# CTRL_MMR0_CFG0 register map
Vendor: Texas Instruments
Registers are 32-bit, read-write, reset 0x0 unless marked. A register's access mark holds for its fields unless they carry their own. Offsets are as the file gives them; [hi:lo] are bit positions; {n}, {i} and the like mark numbered series.

## CTRL_MMR0_CFG0 (part 4 of 10)
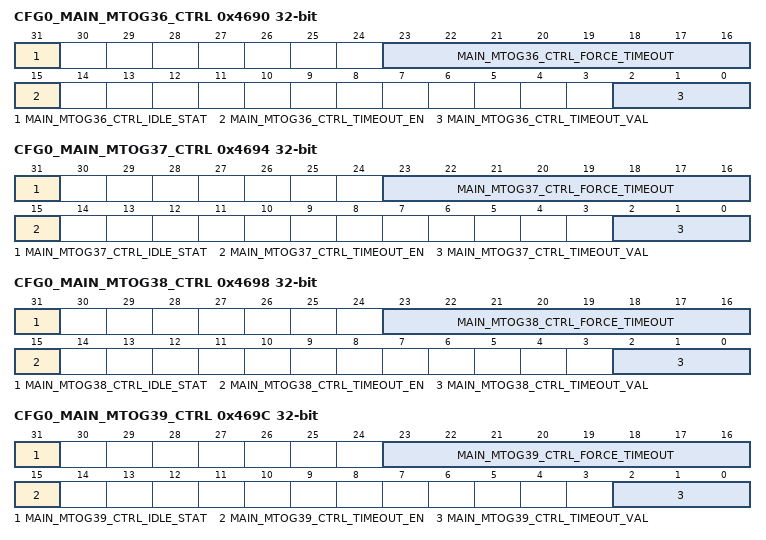
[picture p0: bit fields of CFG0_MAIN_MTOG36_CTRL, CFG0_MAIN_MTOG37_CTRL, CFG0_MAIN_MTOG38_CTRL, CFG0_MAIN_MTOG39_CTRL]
0x4690 CFG0_MAIN_MTOG36_CTRL access per field — Controls timeout operation of Accelerator Cluster ASIL-B master accesses to DDR for OrderIDs 5-9
  [31] MAIN_MTOG36_CTRL_IDLE_STAT ro — Idle statusWhen high, indicates MTOG36 is idle.
  [23:16] MAIN_MTOG36_CTRL_FORCE_TIMEOUT rw — Force TimeoutForces a flush of the interface transactions. This bitfield is only relevant if timeout_en=1. After forcing a timeout by writing the encoded value, the force_timeout and timeout_en bitfields must be cleared to clear the timeout before re-enabling the gasket. 8'h95 - Force a gasket timeoutAll others - Normal operation
  [15] MAIN_MTOG36_CTRL_TIMEOUT_EN rw — Timeout Enable 1'b0 - Disable the gasket. Clear the interrupt and reset the counter 1'b1 - Enable the timeout gasket functions
  [2:0] MAIN_MTOG36_CTRL_TIMEOUT_VAL rw — Gasket Timeout ValueSelects the number of clock cycles before the interface is considered to have timed out Field values (Others are reserved): 3'b000 - 1024 clock cycles 3'b001 - 4096 clock cycles 3'b010 - 16,384 clock cycles 3'b011 - 65,536 clock cycles 3'b100 - 262,144 clock cycles 3'b101 - 1,048,576 clock cycles 3'b110 - 2,097,152 clock cycles 3'b111 - 4,194,303 clock cycles
0x4694 CFG0_MAIN_MTOG37_CTRL access per field — Controls timeout operation of Accelerator Cluster QueueManager master accesses to DDR for OrderIDs 5-9
  [31] MAIN_MTOG37_CTRL_IDLE_STAT ro — Idle statusWhen high, indicates MTOG37 is idle.
  [23:16] MAIN_MTOG37_CTRL_FORCE_TIMEOUT rw — Force TimeoutForces a flush of the interface transactions. This bitfield is only relevant if timeout_en=1. After forcing a timeout by writing the encoded value, the force_timeout and timeout_en bitfields must be cleared to clear the timeout before re-enabling the gasket. 8'h95 - Force a gasket timeoutAll others - Normal operation
  [15] MAIN_MTOG37_CTRL_TIMEOUT_EN rw — Timeout Enable 1'b0 - Disable the gasket. Clear the interrupt and reset the counter 1'b1 - Enable the timeout gasket functions
  [2:0] MAIN_MTOG37_CTRL_TIMEOUT_VAL rw — Gasket Timeout ValueSelects the number of clock cycles before the interface is considered to have timed out Field values (Others are reserved): 3'b000 - 1024 clock cycles 3'b001 - 4096 clock cycles 3'b010 - 16,384 clock cycles 3'b011 - 65,536 clock cycles 3'b100 - 262,144 clock cycles 3'b101 - 1,048,576 clock cycles 3'b110 - 2,097,152 clock cycles 3'b111 - 4,194,303 clock cycles
0x4698 CFG0_MAIN_MTOG38_CTRL access per field — Controls timeout operation of Accelerator Cluster ASIL-B master accesses to DDR for OrderIDs 10-15
  [31] MAIN_MTOG38_CTRL_IDLE_STAT ro — Idle statusWhen high, indicates MTOG38 is idle.
  [23:16] MAIN_MTOG38_CTRL_FORCE_TIMEOUT rw — Force TimeoutForces a flush of the interface transactions. This bitfield is only relevant if timeout_en=1. After forcing a timeout by writing the encoded value, the force_timeout and timeout_en bitfields must be cleared to clear the timeout before re-enabling the gasket. 8'h95 - Force a gasket timeoutAll others - Normal operation
  [15] MAIN_MTOG38_CTRL_TIMEOUT_EN rw — Timeout Enable 1'b0 - Disable the gasket. Clear the interrupt and reset the counter 1'b1 - Enable the timeout gasket functions
  [2:0] MAIN_MTOG38_CTRL_TIMEOUT_VAL rw — Gasket Timeout ValueSelects the number of clock cycles before the interface is considered to have timed out Field values (Others are reserved): 3'b000 - 1024 clock cycles 3'b001 - 4096 clock cycles 3'b010 - 16,384 clock cycles 3'b011 - 65,536 clock cycles 3'b100 - 262,144 clock cycles 3'b101 - 1,048,576 clock cycles 3'b110 - 2,097,152 clock cycles 3'b111 - 4,194,303 clock cycles
0x469C CFG0_MAIN_MTOG39_CTRL access per field — Controls timeout operation of Accelerator Cluster QueueManager master accesses to DDR for OrderIDs 10-15
  [31] MAIN_MTOG39_CTRL_IDLE_STAT ro — Idle statusWhen high, indicates MTOG39 is idle.
  [23:16] MAIN_MTOG39_CTRL_FORCE_TIMEOUT rw — Force TimeoutForces a flush of the interface transactions. This bitfield is only relevant if timeout_en=1. After forcing a timeout by writing the encoded value, the force_timeout and timeout_en bitfields must be cleared to clear the timeout before re-enabling the gasket. 8'h95 - Force a gasket timeoutAll others - Normal operation
  [15] MAIN_MTOG39_CTRL_TIMEOUT_EN rw — Timeout Enable 1'b0 - Disable the gasket. Clear the interrupt and reset the counter 1'b1 - Enable the timeout gasket functions
  [2:0] MAIN_MTOG39_CTRL_TIMEOUT_VAL rw — Gasket Timeout ValueSelects the number of clock cycles before the interface is considered to have timed out Field values (Others are reserved): 3'b000 - 1024 clock cycles 3'b001 - 4096 clock cycles 3'b010 - 16,384 clock cycles 3'b011 - 65,536 clock cycles 3'b100 - 262,144 clock cycles 3'b101 - 1,048,576 clock cycles 3'b110 - 2,097,152 clock cycles 3'b111 - 4,194,303 clock cycles
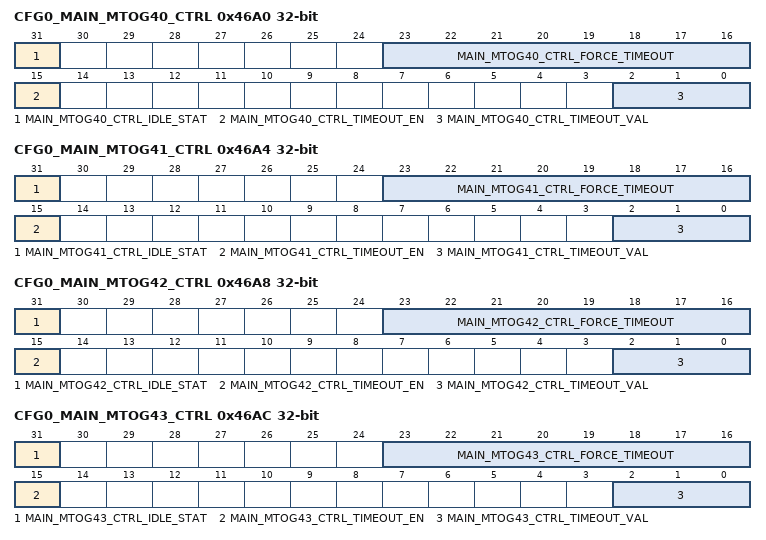
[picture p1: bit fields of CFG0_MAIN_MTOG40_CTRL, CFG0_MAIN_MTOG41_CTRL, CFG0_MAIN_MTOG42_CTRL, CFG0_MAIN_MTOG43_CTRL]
0x46A0 CFG0_MAIN_MTOG40_CTRL access per field — Controls timeout operation of read transactions from the MAIN R5 Clstr2 Core0 VBUSM Memory master port
  [31] MAIN_MTOG40_CTRL_IDLE_STAT ro — Idle statusWhen high, indicates MTOG40 is idle.
  [23:16] MAIN_MTOG40_CTRL_FORCE_TIMEOUT rw — Force TimeoutForces a flush of the interface transactions. This bitfield is only relevant if timeout_en=1. After forcing a timeout by writing the encoded value, the force_timeout and timeout_en bitfields must be cleared to clear the timeout before re-enabling the gasket. 8'h95 - Force a gasket timeoutAll others - Normal operation
  [15] MAIN_MTOG40_CTRL_TIMEOUT_EN rw — Timeout Enable 1'b0 - Disable the gasket. Clear the interrupt and reset the counter 1'b1 - Enable the timeout gasket functions
  [2:0] MAIN_MTOG40_CTRL_TIMEOUT_VAL rw — Gasket Timeout ValueSelects the number of clock cycles before the interface is considered to have timed out Field values (Others are reserved): 3'b000 - 1024 clock cycles 3'b001 - 4096 clock cycles 3'b010 - 16,384 clock cycles 3'b011 - 65,536 clock cycles 3'b100 - 262,144 clock cycles 3'b101 - 1,048,576 clock cycles 3'b110 - 2,097,152 clock cycles 3'b111 - 4,194,303 clock cycles
0x46A4 CFG0_MAIN_MTOG41_CTRL access per field — Controls timeout operation of write transactions from the MAIN R5 Clstr2 Core0 VBUSM Memory master port
  [31] MAIN_MTOG41_CTRL_IDLE_STAT ro — Idle statusWhen high, indicates MTOG41 is idle.
  [23:16] MAIN_MTOG41_CTRL_FORCE_TIMEOUT rw — Force TimeoutForces a flush of the interface transactions. This bitfield is only relevant if timeout_en=1. After forcing a timeout by writing the encoded value, the force_timeout and timeout_en bitfields must be cleared to clear the timeout before re-enabling the gasket. 8'h95 - Force a gasket timeoutAll others - Normal operation
  [15] MAIN_MTOG41_CTRL_TIMEOUT_EN rw — Timeout Enable 1'b0 - Disable the gasket. Clear the interrupt and reset the counter 1'b1 - Enable the timeout gasket functions
  [2:0] MAIN_MTOG41_CTRL_TIMEOUT_VAL rw — Gasket Timeout ValueSelects the number of clock cycles before the interface is considered to have timed out Field values (Others are reserved): 3'b000 - 1024 clock cycles 3'b001 - 4096 clock cycles 3'b010 - 16,384 clock cycles 3'b011 - 65,536 clock cycles 3'b100 - 262,144 clock cycles 3'b101 - 1,048,576 clock cycles 3'b110 - 2,097,152 clock cycles 3'b111 - 4,194,303 clock cycles
0x46A8 CFG0_MAIN_MTOG42_CTRL access per field — Controls timeout operation of read transactions from the MAIN R5 Clstr2 Core1 VBUSM Memory master port
  [31] MAIN_MTOG42_CTRL_IDLE_STAT ro — Idle statusWhen high, indicates MTOG42 is idle.
  [23:16] MAIN_MTOG42_CTRL_FORCE_TIMEOUT rw — Force TimeoutForces a flush of the interface transactions. This bitfield is only relevant if timeout_en=1. After forcing a timeout by writing the encoded value, the force_timeout and timeout_en bitfields must be cleared to clear the timeout before re-enabling the gasket. 8'h95 - Force a gasket timeoutAll others - Normal operation
  [15] MAIN_MTOG42_CTRL_TIMEOUT_EN rw — Timeout Enable 1'b0 - Disable the gasket. Clear the interrupt and reset the counter 1'b1 - Enable the timeout gasket functions
  [2:0] MAIN_MTOG42_CTRL_TIMEOUT_VAL rw — Gasket Timeout ValueSelects the number of clock cycles before the interface is considered to have timed out Field values (Others are reserved): 3'b000 - 1024 clock cycles 3'b001 - 4096 clock cycles 3'b010 - 16,384 clock cycles 3'b011 - 65,536 clock cycles 3'b100 - 262,144 clock cycles 3'b101 - 1,048,576 clock cycles 3'b110 - 2,097,152 clock cycles 3'b111 - 4,194,303 clock cycles
0x46AC CFG0_MAIN_MTOG43_CTRL access per field — Controls timeout operation of write transactions from the MAIN R5 Clstr2 Core1 VBUSM Memory master port
  [31] MAIN_MTOG43_CTRL_IDLE_STAT ro — Idle statusWhen high, indicates MTOG43 is idle.
  [23:16] MAIN_MTOG43_CTRL_FORCE_TIMEOUT rw — Force TimeoutForces a flush of the interface transactions. This bitfield is only relevant if timeout_en=1. After forcing a timeout by writing the encoded value, the force_timeout and timeout_en bitfields must be cleared to clear the timeout before re-enabling the gasket. 8'h95 - Force a gasket timeoutAll others - Normal operation
  [15] MAIN_MTOG43_CTRL_TIMEOUT_EN rw — Timeout Enable 1'b0 - Disable the gasket. Clear the interrupt and reset the counter 1'b1 - Enable the timeout gasket functions
  [2:0] MAIN_MTOG43_CTRL_TIMEOUT_VAL rw — Gasket Timeout ValueSelects the number of clock cycles before the interface is considered to have timed out Field values (Others are reserved): 3'b000 - 1024 clock cycles 3'b001 - 4096 clock cycles 3'b010 - 16,384 clock cycles 3'b011 - 65,536 clock cycles 3'b100 - 262,144 clock cycles 3'b101 - 1,048,576 clock cycles 3'b110 - 2,097,152 clock cycles 3'b111 - 4,194,303 clock cycles
0x46C0 CFG0_CC_FLUSH_CTRL0 — This register is used isolate the MSMC ARM Corepac 0 interface from other MSMC transactions in case of an ARM Corepac access hang. This allows continuation of other MSMC traffic (e.g. R5 processors) without interference. After asserting this flush, the ARM Corepac can be forced through a power cycle sequence to clear the hang condition. (See Compute Cluster Spec for sequence details.)
  [7:0] CC_FLUSH_CTRL0_FLUSH — Flush ARM / MSMC Interface TransactionsForces a flush of the A72 MSMC interface. This bit field can be used to force a flush of A72 transactions to the MSMC and force an auto response of any MSMC snoop requests to the A72. An encoded bit value is used to prevent accidental activation of the flush signal. 8'h95 - Force a flush (FFI Mode) condition (flush signal driven high)All others - Normal operation (flush signal driven low)
0x46C4 CFG0_CC_FLUSH_CTRL1 — This register is used isolate the MSMC ARM Corepac 1 interface from other MSMC transactions in case of an ARM Corepac access hang. This allows continuation of other MSMC traffic (e.g. R5 processors) without interference. After asserting this flush, the ARM Corepac can be forced through a power cycle sequence to clear the hang condition. (See Compute Cluster Spec for sequence details.)
  [7:0] CC_FLUSH_CTRL1_FLUSH — Flush ARM / MSMC Interface TransactionsForces a flush of the A72 MSMC interface. This bit field can be used to force a flush of A72 transactions to the MSMC and force an auto response of any MSMC snoop requests to the A72. An encoded bit value is used to prevent accidental activation of the flush signal. 8'h95 - Force a flush (FFI Mode) condition (flush signal driven high)All others - Normal operation (flush signal driven low)
{0x46C0+4i} CFG0_CC_FLUSH_CTRL{i} (i=4..7) — This register is used isolate the MSMC C7x Corepac {i} (C71x_{i-4}) interface from other MSMC transactions in case of an C7x Corepac access hang. This allows continuation of other MSMC traffic (e.g. R5 processors) without interference. After asserting this flush, the C7x Corepac can be forced through a power cycle sequence to clear the hang condition. (See Compute Cluster Spec for sequence details.)
  [7:0] CC_FLUSH_CTRL{i}_FLUSH — Flush C7x / MSMC Interface TransactionsForces a flush of the C7x MSMC interface. This bit field can be used to force a flush of C7x transactions to the MSMC and force an auto response of any MSMC snoop requests to the C7x. An encoded bit value is used to prevent accidental activation of the flush signal. 8'h95 - Force a flush (FFI Mode) condition (flush signal driven high)All others - Normal operation (flush signal driven low)
0x46E0 CFG0_CC_FLUSH_CTRL8 — This register is used isolate the MSMC DRU 0 Interfaces from other MSMC transactions in case of a DRU 0 access hang. This allows continuation of other MSMC traffic (e.g. R5 processors) without interference. After asserting this flush, the DRU can be forced through a power cycle sequence to clear the hang condition. (See Compute Cluster Spec for sequence details.)
  [7:0] CC_FLUSH_CTRL8_FLUSH — Flush DRU 0 / MSMC Interface TransactionsForces a flush of the DRU 0 MSMC interface. This bit field can be used to force a flush of DRU 0 transactions to the MSMC and force an auto response of any MSMC snoop requests to the DRU. An encoded bit value is used to prevent accidental activation of the flush signal. 8'h95 - Force a flush (FFI Mode) condition (flush signal driven high)All others - Normal operation (flush signal driven low)
{0x46C0+4i} CFG0_CC_FLUSH_CTRL{i} (i=12..15) — This register is used isolate the MSMC/Analytics DRU {i-8} Interface from other MSMC transactions in case of an Analytics DRU {i-8} access hang. This allows continuation of other MSMC traffic (e.g. R5 processors) without interference. After asserting this flush, the Analytics DRU can be forced through a power cycle sequence to clear the hang condition. (See Compute Cluster Spec for sequence details.)
  [7:0] CC_FLUSH_CTRL{i}_FLUSH — Flush Analytics DRU {i-8} / MSMC Interface TransactionsForces a flush of the Analytics DRU {i-8} MSMC interface. This bit field can be used to force a flush of Analytics DRU transactions to the MSMC and force an auto response of any MSMC snoop requests to the DRU. An encoded bit value is used to prevent accidental activation of the flush signal. 8'h95 - Force a flush (FFI Mode) condition (flush signal driven high)All others - Normal operation (flush signal driven low)
{0x5100+4i} CFG0_CLAIMREG_P1_R{i}_READONLY ro (i=0..14)
  [31:0] CLAIMREG_P1_R{i}_READONLY — Claim bits for Partition 1
0x6000 CFG0_USB0_CTRL_PROXY — Controls USB0 operation
  [27] USB0_CTRL_SERDES_SEL_PROXY — Serdes Selection.The USB3_0 interface can be mapped to 2 different SERDES lanes. This bit selects which SERDES drives the USB3 PIPE interface input clock, data and control signals. Programming should align with the SERDES0_LN3_CTRL and SERDES2_LN3_CTRL lane_func_sel programming. 0 - SERDES0 Ln3 drives USB3_0 inputs 1 - SERDES4 Ln3 drives USB3_0 inputs
0x6008 CFG0_USB0_PHY_CTRL_PROXY reset 0x80000000 — Configures the USB0 Phy operation
  [31] USB0_PHY_CTRL_CORE_VOLTAGE_PROXY — Selects the USB PHY core voltage 0 - Core voltage is 0.85 V 1 - Core voltage is 0.80 V
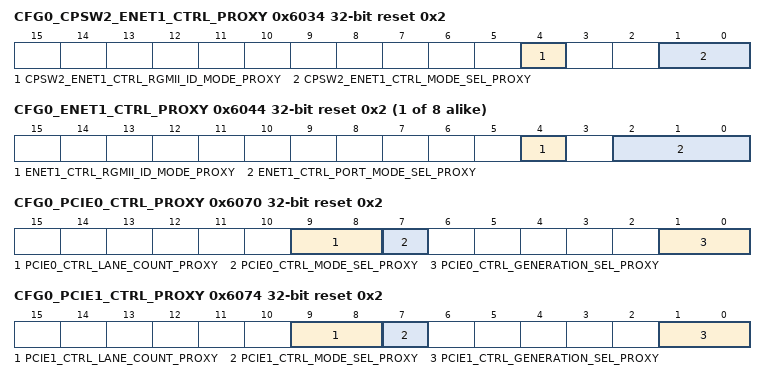
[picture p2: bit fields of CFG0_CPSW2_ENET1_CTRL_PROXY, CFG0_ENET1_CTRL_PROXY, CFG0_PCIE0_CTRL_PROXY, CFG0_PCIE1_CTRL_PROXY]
0x6034 CFG0_CPSW2_ENET1_CTRL_PROXY reset 0x2 — Controls MAIN CPSW_2G Ethernet Port1 operation
  [4] CPSW2_ENET1_CTRL_RGMII_ID_MODE_PROXY — Port 1 RGMII internal transmit delay selection 0 - Internal transmit delay 1 - No internal transmit delay
  [1:0] CPSW2_ENET1_CTRL_MODE_SEL_PROXY — Selects Ethernet switch Port1 interface Field values (Others are reserved): 2'b00 - GMII/MII (not supported) 2'b01 - RMII 2'b10 - RGMII 2'b11 - SGMII (not supported)
{0x6040+4i} CFG0_ENET{i}_CTRL_PROXY reset 0x2 (i=1..8) — Controls Ethernet Port{i} operation
  [4] ENET{i}_CTRL_RGMII_ID_MODE_PROXY — Port{i} RGMII internal transmit delay selection 0 - Internal transmit delay 1 - No internal transmit delay
  [2:0] ENET{i}_CTRL_PORT_MODE_SEL_PROXY — Selects Ethernet switch Port{i} interface Field values (Others are reserved): 3'b000 - GMII/MII (not supported) 3'b001 - RMII (not supported) 3'b010 - RGMII (not supported) 3'b011 - SGMII 3'b100 - QSGMII 3'b101 - USXGMII/XFI 3'b110 - QSGMII_SUB 3'b111 - Reserved
0x6070 CFG0_PCIE0_CTRL_PROXY reset 0x2 — Controls PCIe0 operation
  [9:8] PCIE0_CTRL_LANE_COUNT_PROXY — Configures the PCIe lane count 00 - Select 1-lane operation 01 - Select 2-lane operation 1x - Select 4-lane operation
  [7] PCIE0_CTRL_MODE_SEL_PROXY — Selects the operating mode 0 - Endpoint 1 - Root Complex
  [1:0] PCIE0_CTRL_GENERATION_SEL_PROXY — Configures the PCIe generation support in the PCIe capabilities linked-list Field values (Others are reserved): 2'b01 - Gen2 - Controller advertises Gen1 & Gen2 capability and link operates at either speed 2'b10 - Gen3 - Controller advertises Gen1, Gen2, & Gen3 capability and link operates at any of the three speeds 2'b11 - Reserved
0x6074 CFG0_PCIE1_CTRL_PROXY reset 0x2 — Controls PCIe1 operation
  [9:8] PCIE1_CTRL_LANE_COUNT_PROXY — Configures the PCIe lane count 00 - Select 1-lane operation 01 - Select 2-lane operation 1x - Select 4-lane operation
  [7] PCIE1_CTRL_MODE_SEL_PROXY — Selects the operating mode 0 - Endpoint 1 - Root Complex
  [1:0] PCIE1_CTRL_GENERATION_SEL_PROXY — Configures the PCIe generation support in the PCIe capabilities linked-list Field values (Others are reserved): 2'b01 - Gen2 - Controller advertises Gen1 & Gen2 capability and link operates at either speed 2'b10 - Gen3 - Controller advertises Gen1, Gen2, & Gen3 capability and link operates at any of the three speeds 2'b11 - Reserved
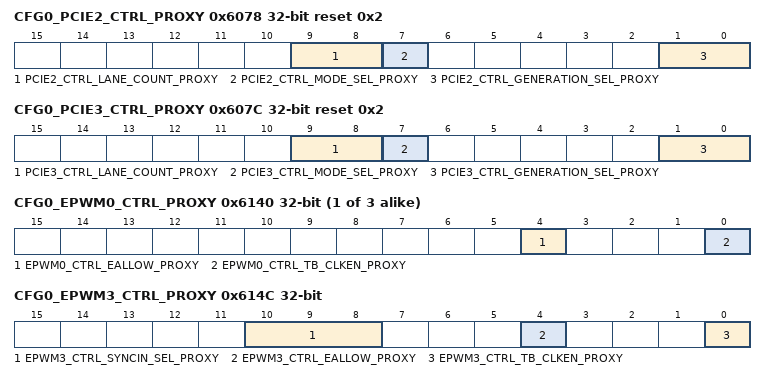
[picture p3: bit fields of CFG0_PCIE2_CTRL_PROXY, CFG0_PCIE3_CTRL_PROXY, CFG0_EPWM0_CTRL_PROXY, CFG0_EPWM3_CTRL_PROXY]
0x6078 CFG0_PCIE2_CTRL_PROXY reset 0x2 — Controls PCIe2 operation
  [9:8] PCIE2_CTRL_LANE_COUNT_PROXY — Configures the PCIe lane count 00 - Select 1-lane operation 01 - Select 2-lane operation 1x - Select 4-lane operation (not supported)
  [7] PCIE2_CTRL_MODE_SEL_PROXY — Selects the operating mode 0 - Endpoint 1 - Root Complex
  [1:0] PCIE2_CTRL_GENERATION_SEL_PROXY — Configures the PCIe generation support in the PCIe capabilities linked-list Field values (Others are reserved): 2'b01 - Gen2 - Controller advertises Gen1 & Gen2 capability and link operates at either speed 2'b10 - Gen3 - Controller advertises Gen1, Gen2, & Gen3 capability and link operates at any of the three speeds 2'b11 - Reserved
0x607C CFG0_PCIE3_CTRL_PROXY reset 0x2 — Controls PCIe3 operation
  [9:8] PCIE3_CTRL_LANE_COUNT_PROXY — Configures the PCIe lane count 00 - Select 1-lane operation 01 - Select 2-lane operation 1x - Select 4-lane operation (not supported)
  [7] PCIE3_CTRL_MODE_SEL_PROXY — Selects the operating mode 0 - Endpoint 1 - Root Complex
  [1:0] PCIE3_CTRL_GENERATION_SEL_PROXY — Configures the PCIe generation support in the PCIe capabilities linked-list Field values (Others are reserved): 2'b01 - Gen2 - Controller advertises Gen1 & Gen2 capability and link operates at either speed 2'b10 - Gen3 - Controller advertises Gen1, Gen2, & Gen3 capability and link operates at any of the three speeds 2'b11 - Reserved
0x6080 CFG0_SERDES0_LN0_CTRL_PROXY — Controls SERDES0 lane0 selection
  [1:0] SERDES0_LN0_CTRL_LANE_FUNC_SEL_PROXY — Selects the SERDES0 lane0 function Field values (Others are reserved): 2'b00 - IP1 - Not Used 2'b01 - IP2 - PCIe1 Lane 0 2'b10 - IP3 - Not used 2'b11 - IP4 - Hyperlink (VUSR) Lane 0
0x6084 CFG0_SERDES0_LN1_CTRL_PROXY — Controls SERDES0 lane1 selection
  [1:0] SERDES0_LN1_CTRL_LANE_FUNC_SEL_PROXY — Selects the SERDES0 lane1 function Field values (Others are reserved): 2'b00 - IP1 - Not Used 2'b01 - IP2 - PCIe1 Lane 1 2'b10 - IP3 - Not Used 2'b11 - IP4 - Hyperlink (VUSR) Lane 1
0x6088 CFG0_SERDES0_LN2_CTRL_PROXY — Controls SERDES0 lane2 selection
  [1:0] SERDES0_LN2_CTRL_LANE_FUNC_SEL_PROXY — Selects the SERDES0 lane2 function Field values (Others are reserved): 2'b00 - IP1 - PCIe3 Lane 0 2'b01 - IP2 - PCIe1 Lane 2 2'b10 - IP3 - Not Used 2'b11 - Ip4 - Hyperlink (VUSR) Lane 2
0x608C CFG0_SERDES0_LN3_CTRL_PROXY — Controls SERDES0 lane3 selection
  [1:0] SERDES0_LN3_CTRL_LANE_FUNC_SEL_PROXY — Selects the SERDES0 lane3 function Field values (Others are reserved): 2'b00 - IP1 - PCIe3 Lane 1 2'b01 - IP2 - PCIe1 Lane 3 2'b10 - IP3 - USB3_0 2'b11 - IP4 - Hyperlink (VUSR) Lane 3
0x6090 CFG0_SERDES1_LN0_CTRL_PROXY — Controls SERDES1 lane0 selection
  [1:0] SERDES1_LN0_CTRL_LANE_FUNC_SEL_PROXY — Selects the SERDES1 lane0 function Field values (Others are reserved): 2'b00 - IP1 - Enet Switch Q/SGMII Lane 3 2'b01 - IP2 - PCIe0 Lane 0 2'b10 - IP3 - Not Used 2'b11 - IP4 - Not Used
0x6094 CFG0_SERDES1_LN1_CTRL_PROXY — Controls SERDES1 lane1 selection
  [1:0] SERDES1_LN1_CTRL_LANE_FUNC_SEL_PROXY — Selects the SERDES1 lane1 function Field values (Others are reserved): 2'b00 - IP1 - Enet Switch Q/SGMII Lane 4 2'b01 - IP2 - PCIe0 Lane 1 2'b10 - IP3 - Not Used 2'b11 - IP4 - Not Used
0x6098 CFG0_SERDES1_LN2_CTRL_PROXY — Controls SERDES1 lane2 selection
  [1:0] SERDES1_LN2_CTRL_LANE_FUNC_SEL_PROXY — Selects the SERDES1 lane2 function Field values (Others are reserved): 2'b00 - IP1 - Enet Switch Q/SGMII Lane 1 2'b01 - IP2 - PCIe0 Lane 2 2'b10 - IP3 - PCIe2 Lane 0 2'b11 - IP4 - Not Used
0x609C CFG0_SERDES1_LN3_CTRL_PROXY — Controls SERDES1 lane3 selection
  [1:0] SERDES1_LN3_CTRL_LANE_FUNC_SEL_PROXY — Selects the SERDES1 lane3 function Field values (Others are reserved): 2'b00 - IP1 - Enet Switch Q/SGMII Lane 2 2'b01 - IP2 - PCIe0 Lane 3 2'b10 - IP3 - PCIe2 Lane 1 2'b11 - IP4 - Not Used
0x60A0 CFG0_SERDES2_LN0_CTRL_PROXY — Controls SERDES2 lane0 selection
  [1:0] SERDES2_LN0_CTRL_LANE_FUNC_SEL_PROXY — Selects the SERDES2 lane0 function Field values (Others are reserved): 2'b00 - IP1 - Enet Switch Q/SGMII Lane 5 2'b01 - IP2 - Not Used 2'b10 - IP3 - Not Used 2'b11 - IP4 - Not Used
0x60A4 CFG0_SERDES2_LN1_CTRL_PROXY — Controls SERDES2 lane1 selection
  [1:0] SERDES2_LN1_CTRL_LANE_FUNC_SEL_PROXY — Selects the SERDES2 lane1 function Field values (Others are reserved): 2'b00 - IP1 - Enet Switch Q/SGMII Lane 6 2'b01 - IP2 - Not Used 2'b10 - IP3 - Not Used 2'b11 - IP4 - Not Used
0x60A8 CFG0_SERDES2_LN2_CTRL_PROXY — Controls SERDES2 lane2 selection
  [1:0] SERDES2_LN2_CTRL_LANE_FUNC_SEL_PROXY — Selects the SERDES2 lane2 functionProgramming this value to 2'b01 also selects SerDes2 to drive the CPSW Lane 0 PIPE interface input clock, data, and control signals. Field values (Others are reserved): 2'b00 - IP1 - Enet Switch Q/SGMII Lane 7 2'b01 - IP2 - Enet Switch Q/SGMII Lane 1 2'b10 - IP3 - Not Used 2'b11 - IP4 - Not Used
0x60AC CFG0_SERDES2_LN3_CTRL_PROXY — Controls SERDES2 lane3 selection
  [1:0] SERDES2_LN3_CTRL_LANE_FUNC_SEL_PROXY — Selects the SERDES2 lane3 functionProgramming this value to 2'b01 also selects SerDes2 to drive the CPSW Lane 1 PIPE interface input clock, data, and control signals. Field values (Others are reserved): 2'b00 - IP1 - Enet Switch Q/SGMII Lane 8 2'b01 - IP2 - Enet Switch Q/SGMII Lane 2 2'b10 - IP3 - Not Used 2'b11 - IP4 - Not Used
{0x60C0+4i} CFG0_SERDES4_LN{i}_CTRL_PROXY (i=0..2) — Controls SERDES4 lane{i} selection
  [1:0] SERDES4_LN{i}_CTRL_LANE_FUNC_SEL_PROXY — Selects the SERDES4 lane{i} functionProgramming this value to 2'b01 also selects SerDes4 to drive the CPSW Lane {i+5} PIPE interface input clock, data and control signals. Field values (Others are reserved): 2'b00 - IP1 - eDP Lane {i} 2'b01 - IP2 - Enet Switch Q/SGMII Lane {i+5} 2'b10 - IP3 - Not Used 2'b11 - IP4 - Hyperlink (VUSR) Lane {i}
0x60CC CFG0_SERDES4_LN3_CTRL_PROXY — Controls SERDES4 lane3 selection
  [1:0] SERDES4_LN3_CTRL_LANE_FUNC_SEL_PROXY — Selects the SERDES4 lane3 functionProgramming this value to 2'b01 also selects SerDes4 to drive the CPSW Lane 8 PIPE interface input clock, data and control signals. Field values (Others are reserved): 2'b00 - IP1 - eDP Lane 3 2'b01 - IP2 - Enet Switch Q/SGMII Lane 8 2'b10 - IP3 - USB3_0 2'b11 - IP4 - Hyperlink (VUSR) Lane 3
{0x60E0+4i} CFG0_SERDES{i}_CTRL_PROXY (i=0..2) — Controls SERDES{i} operation
  [8] SERDES{i}_CTRL_RET_EN_PROXY — Retention enable
0x60F0 CFG0_SERDES4_CTRL_PROXY — Controls SERDES4 operation
  [8] SERDES4_CTRL_RET_EN_PROXY — Retention enable
{0x6140+4i} CFG0_EPWM{i}_CTRL_PROXY (i=0..2) — Controls ePWM{i} Operation
  [4] EPWM{i}_CTRL_EALLOW_PROXY — Enable write access to ePWM tripzone and HRPWM config registers 0 - Disabled 1 - Enabled
  [0] EPWM{i}_CTRL_TB_CLKEN_PROXY — Enable ePWM timebase clock 0 - Disabled 1 - EnabledThis bit is OR'd with SUP_CTRL7_pwm{i}_tb_clken. Setting the tb_clken in either register will start the timebase counter.
0x614C CFG0_EPWM3_CTRL_PROXY — Controls ePWM3 Operation
  [10:8] EPWM3_CTRL_SYNCIN_SEL_PROXY — Selects the source of the PWM3 synchronization input Field values (Others are reserved): 3'b000 - PWM3_SYNCIN Pin 3'b001 - PWM2 syncout signal, daisy chained 3'b010 - None 3'b011 - None 3'b100 - None 3'b101 - None 3'b110 - None 3'b111 - None
  [4] EPWM3_CTRL_EALLOW_PROXY — Enable write access to ePWM tripzone and HRPWM config registers 0 - Disabled 1 - Enabled
  [0] EPWM3_CTRL_TB_CLKEN_PROXY — Enable ePWM timebase clock 0 - Disabled 1 - EnabledThis bit is OR'd with SUP_CTRL7_pwm3_tb_clken. Setting the tb_clken in either register will start the timebase counter.
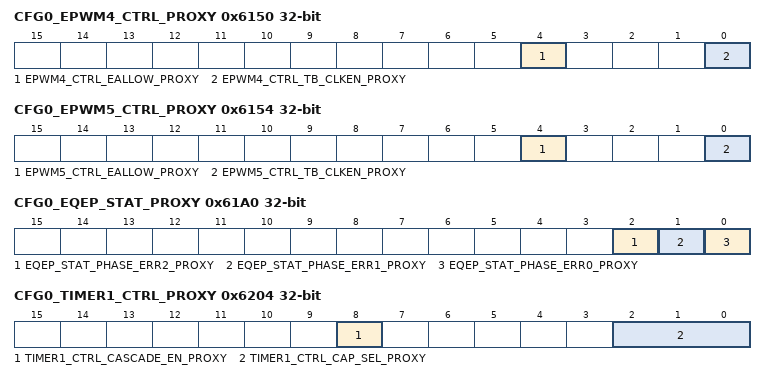
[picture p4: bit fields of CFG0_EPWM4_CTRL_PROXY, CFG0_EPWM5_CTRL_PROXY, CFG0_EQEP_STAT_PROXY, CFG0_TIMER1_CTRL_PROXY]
0x6150 CFG0_EPWM4_CTRL_PROXY — Controls ePWM4 Operation
  [4] EPWM4_CTRL_EALLOW_PROXY — Enable write access to ePWM tripzone and HRPWM config registers 0 - Disabled 1 - Enabled
  [0] EPWM4_CTRL_TB_CLKEN_PROXY — Enable ePWM timebase clock 0 - Disabled 1 - EnabledThis bit is OR'd with SUP_CTRL7_pwm4_tb_clken. Setting the tb_clken in either register will start the timebase counter.
0x6154 CFG0_EPWM5_CTRL_PROXY — Controls ePWM5 Operation
  [4] EPWM5_CTRL_EALLOW_PROXY — Enable write access to ePWM tripzone and HRPWM config registers 0 - Disabled 1 - Enabled
  [0] EPWM5_CTRL_TB_CLKEN_PROXY — Enable ePWM timebase clock 0 - Disabled 1 - EnabledThis bit is OR'd with SUP_CTRL7_pwm5_tb_clken. Setting the tb_clken in either register will start the timebase counter.
0x6160 CFG0_SOCA_SEL_PROXY — Selects Start of Conversion A output signal source. Each ePWM provides a SOCA event that can be used to trigger external ADCs. All ePWM SOCA events are ORed together allowing any of the 6 ePWMs to generate the event (if enabled within the ePWM). This event is then muxed with an ICSSx host interrupt allowing either an ICSSx or ePWMs to source the SOCA event pin.
  [1:0] SOCA_SEL_SOCA_SEL_PROXY — Selects the SOC A output source Field values (Others are reserved): 2'b00 - OR of all eHRPWM SOCA outputs 2'b01 - None 2'b10 - None 2'b11 - None
0x6164 CFG0_SOCB_SEL_PROXY — Selects Start of Conversion B output signal source.. Each ePWM provides a SOCB event that can be used to trigger external ADCs. All ePWM SOCB events are ORed together allowing any of the 6 ePWMs to generate the event (if enabled within the ePWM).
  [1:0] SOCB_SEL_SOCB_SEL_PROXY — Selects the SOC B output source Field values (Others are reserved): 2'b00 - OR of all eHRPWM SOCB ouputs 2'b01 - None 2'b10 - None 2'b11 - None
0x61A0 CFG0_EQEP_STAT_PROXY ro — Displays status of EQEP modules
  [2] EQEP_STAT_PHASE_ERR2_PROXY — eQEP2 Phase error status 0 - No error 1 - Phase error occurred
  [1] EQEP_STAT_PHASE_ERR1_PROXY — eQEP1 Phase error status 0 - No error 1 - Phase error occurred
  [0] EQEP_STAT_PHASE_ERR0_PROXY — eQEP0 Phase error status 0 - No error 1 - Phase error occurred
0x61B4 CFG0_SDIO1_CTRL_PROXY — Controls drive strength of MMC1 SDIO mode pins
  [4:0] SDIO1_CTRL_DRV_STR_PROXY — Selects the SDIO drive strength
0x6200 CFG0_TIMER0_CTRL_PROXY — Controls TIMER0 operation
  [2:0] TIMER0_CTRL_CAP_SEL_PROXY — Selects the TIMERIO input pin for capture input signal. This control is only used when TIMER0 is configured for capture operation. Field values (Others are reserved): 3'b000 - Use TIMERIO0 pin 3'b001 - Use TIMERIO1 pin 3'b010 - Use TIMERIO2 pin 3'b011 - Use TIMERIO3 pin 3'b100 - Use TIMERIO4 pin 3'b101 - Use TIMERIO5 pin 3'b110 - Use TIMERIO6 pin 3'b111 - Use TIMERIO7 pin
0x6204 CFG0_TIMER1_CTRL_PROXY — Controls TIMER1 operation
  [8] TIMER1_CTRL_CASCADE_EN_PROXY — Enables cascading of TIMER1 to TIMER0
  [2:0] TIMER1_CTRL_CAP_SEL_PROXY — Selects the TIMERIO input pin for capture input signal. This control is only used when TIMER1 is configured for capture operation. Field values (Others are reserved): 3'b000 - Use TIMERIO0 pin 3'b001 - Use TIMERIO1 pin 3'b010 - Use TIMERIO2 pin 3'b011 - Use TIMERIO3 pin 3'b100 - Use TIMERIO4 pin 3'b101 - Use TIMERIO5 pin 3'b110 - Use TIMERIO6 pin 3'b111 - Use TIMERIO7 pin
0x6208 CFG0_TIMER2_CTRL_PROXY — Controls TIMER2 operation
  [2:0] TIMER2_CTRL_CAP_SEL_PROXY — Selects the TIMERIO input pin for capture input signal. This control is only used when TIMER2 is configured for capture operation. Field values (Others are reserved): 3'b000 - Use TIMERIO0 pin 3'b001 - Use TIMERIO1 pin 3'b010 - Use TIMERIO2 pin 3'b011 - Use TIMERIO3 pin 3'b100 - Use TIMERIO4 pin 3'b101 - Use TIMERIO5 pin 3'b110 - Use TIMERIO6 pin 3'b111 - Use TIMERIO7 pin
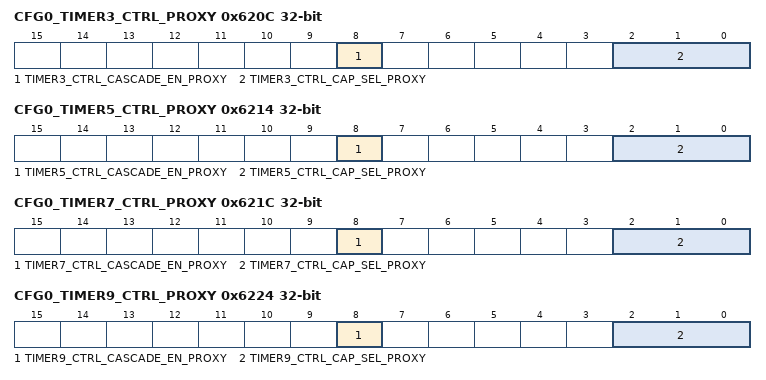
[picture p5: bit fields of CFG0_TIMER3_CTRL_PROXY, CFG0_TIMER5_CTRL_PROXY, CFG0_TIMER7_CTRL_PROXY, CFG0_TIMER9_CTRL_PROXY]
0x620C CFG0_TIMER3_CTRL_PROXY — Controls TIMER3 operation
  [8] TIMER3_CTRL_CASCADE_EN_PROXY — Enables cascading of TIMER3 to TIMER2
  [2:0] TIMER3_CTRL_CAP_SEL_PROXY — Selects the TIMERIO input pin for capture input signal. This control is only used when TIMER3 is configured for capture operation. Field values (Others are reserved): 3'b000 - Use TIMERIO0 pin 3'b001 - Use TIMERIO1 pin 3'b010 - Use TIMERIO2 pin 3'b011 - Use TIMERIO3 pin 3'b100 - Use TIMERIO4 pin 3'b101 - Use TIMERIO5 pin 3'b110 - Use TIMERIO6 pin 3'b111 - Use TIMERIO7 pin
0x6210 CFG0_TIMER4_CTRL_PROXY — Controls TIMER4 operation
  [2:0] TIMER4_CTRL_CAP_SEL_PROXY — Selects the TIMERIO input pin for capture input signal. This control is only used when TIMER4 is configured for capture operation. Field values (Others are reserved): 3'b000 - Use TIMERIO0 pin 3'b001 - Use TIMERIO1 pin 3'b010 - Use TIMERIO2 pin 3'b011 - Use TIMERIO3 pin 3'b100 - Use TIMERIO4 pin 3'b101 - Use TIMERIO5 pin 3'b110 - Use TIMERIO6 pin 3'b111 - Use TIMERIO7 pin
0x6214 CFG0_TIMER5_CTRL_PROXY — Controls TIMER5 operation
  [8] TIMER5_CTRL_CASCADE_EN_PROXY — Enables cascading of TIMER5 to TIMER4
  [2:0] TIMER5_CTRL_CAP_SEL_PROXY — Selects the TIMERIO input pin for capture input signal. This control is only used when TIMER5 is configured for capture operation. Field values (Others are reserved): 3'b000 - Use TIMERIO0 pin 3'b001 - Use TIMERIO1 pin 3'b010 - Use TIMERIO2 pin 3'b011 - Use TIMERIO3 pin 3'b100 - Use TIMERIO4 pin 3'b101 - Use TIMERIO5 pin 3'b110 - Use TIMERIO6 pin 3'b111 - Use TIMERIO7 pin
0x6218 CFG0_TIMER6_CTRL_PROXY — Controls TIMER6 operation
  [2:0] TIMER6_CTRL_CAP_SEL_PROXY — Selects the TIMERIO input pin for capture input signal. This control is only used when TIMER6 is configured for capture operation. Field values (Others are reserved): 3'b000 - Use TIMERIO0 pin 3'b001 - Use TIMERIO1 pin 3'b010 - Use TIMERIO2 pin 3'b011 - Use TIMERIO3 pin 3'b100 - Use TIMERIO4 pin 3'b101 - Use TIMERIO5 pin 3'b110 - Use TIMERIO6 pin 3'b111 - Use TIMERIO7 pin
0x621C CFG0_TIMER7_CTRL_PROXY — Controls TIMER7 operation
  [8] TIMER7_CTRL_CASCADE_EN_PROXY — Enables cascading of TIMER7 to TIMER6
  [2:0] TIMER7_CTRL_CAP_SEL_PROXY — Selects the TIMERIO input pin for capture input signal. This control is only used when TIMER7 is configured for capture operation. Field values (Others are reserved): 3'b000 - Use TIMERIO0 pin 3'b001 - Use TIMERIO1 pin 3'b010 - Use TIMERIO2 pin 3'b011 - Use TIMERIO3 pin 3'b100 - Use TIMERIO4 pin 3'b101 - Use TIMERIO5 pin 3'b110 - Use TIMERIO6 pin 3'b111 - Use TIMERIO7 pin
0x6220 CFG0_TIMER8_CTRL_PROXY — Controls TIMER8 operation
  [2:0] TIMER8_CTRL_CAP_SEL_PROXY — Selects the TIMERIO input pin for capture input signal. This control is only used when TIMER8 is configured for capture operation. Field values (Others are reserved): 3'b000 - Use TIMERIO0 pin 3'b001 - Use TIMERIO1 pin 3'b010 - Use TIMERIO2 pin 3'b011 - Use TIMERIO3 pin 3'b100 - Use TIMERIO4 pin 3'b101 - Use TIMERIO5 pin 3'b110 - Use TIMERIO6 pin 3'b111 - Use TIMERIO7 pin
0x6224 CFG0_TIMER9_CTRL_PROXY — Controls TIMER9 operation
  [8] TIMER9_CTRL_CASCADE_EN_PROXY — Enables cascading of TIMER9 to TIMER8
  [2:0] TIMER9_CTRL_CAP_SEL_PROXY — Selects the TIMERIO input pin for capture input signal. This control is only used when TIMER9 is configured for capture operation. Field values (Others are reserved): 3'b000 - Use TIMERIO0 pin 3'b001 - Use TIMERIO1 pin 3'b010 - Use TIMERIO2 pin 3'b011 - Use TIMERIO3 pin 3'b100 - Use TIMERIO4 pin 3'b101 - Use TIMERIO5 pin 3'b110 - Use TIMERIO6 pin 3'b111 - Use TIMERIO7 pin
0x6228 CFG0_TIMER10_CTRL_PROXY — Controls TIMER10 operation
  [2:0] TIMER10_CTRL_CAP_SEL_PROXY — Selects the TIMERIO input pin for capture input signal. This control is only used when TIMER10 is configured for capture operation. Field values (Others are reserved): 3'b000 - Use TIMERIO0 pin 3'b001 - Use TIMERIO1 pin 3'b010 - Use TIMERIO2 pin 3'b011 - Use TIMERIO3 pin 3'b100 - Use TIMERIO4 pin 3'b101 - Use TIMERIO5 pin 3'b110 - Use TIMERIO6 pin 3'b111 - Use TIMERIO7 pin
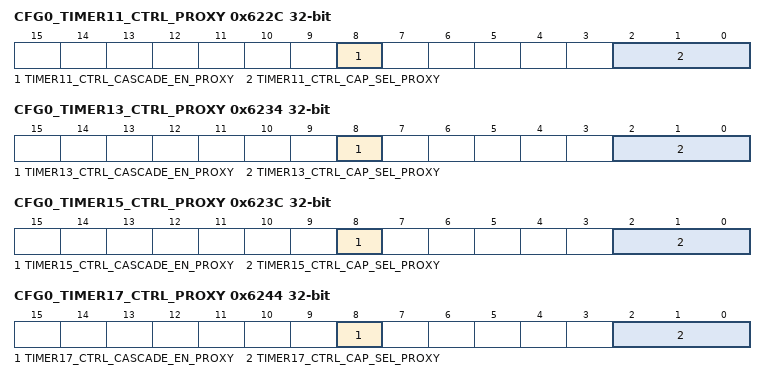
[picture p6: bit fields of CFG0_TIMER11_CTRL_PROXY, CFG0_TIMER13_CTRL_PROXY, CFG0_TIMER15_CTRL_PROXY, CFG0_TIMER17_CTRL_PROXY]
0x622C CFG0_TIMER11_CTRL_PROXY — Controls TIMER11 operation
  [8] TIMER11_CTRL_CASCADE_EN_PROXY — Enables cascading of TIMER11 to TIMER10
  [2:0] TIMER11_CTRL_CAP_SEL_PROXY — Selects the TIMERIO input pin for capture input signal. This control is only used when TIMER11 is configured for capture operation. Field values (Others are reserved): 3'b000 - Use TIMERIO0 pin 3'b001 - Use TIMERIO1 pin 3'b010 - Use TIMERIO2 pin 3'b011 - Use TIMERIO3 pin 3'b100 - Use TIMERIO4 pin 3'b101 - Use TIMERIO5 pin 3'b110 - Use TIMERIO6 pin 3'b111 - Use TIMERIO7 pin
0x6230 CFG0_TIMER12_CTRL_PROXY — Controls TIMER12 operation
  [2:0] TIMER12_CTRL_CAP_SEL_PROXY — Selects the TIMERIO input pin for capture input signal. This control is only used when TIMER12 is configured for capture operation. Field values (Others are reserved): 3'b000 - Use TIMERIO0 pin 3'b001 - Use TIMERIO1 pin 3'b010 - Use TIMERIO2 pin 3'b011 - Use TIMERIO3 pin 3'b100 - Use TIMERIO4 pin 3'b101 - Use TIMERIO5 pin 3'b110 - Use TIMERIO6 pin 3'b111 - Use TIMERIO7 pin
0x6234 CFG0_TIMER13_CTRL_PROXY — Controls TIMER13 operation
  [8] TIMER13_CTRL_CASCADE_EN_PROXY — Enables cascading of TIMER13 to TIMER12
  [2:0] TIMER13_CTRL_CAP_SEL_PROXY — Selects the TIMERIO input pin for capture input signal. This control is only used when TIMER13 is configured for capture operation. Field values (Others are reserved): 3'b000 - Use TIMERIO0 pin 3'b001 - Use TIMERIO1 pin 3'b010 - Use TIMERIO2 pin 3'b011 - Use TIMERIO3 pin 3'b100 - Use TIMERIO4 pin 3'b101 - Use TIMERIO5 pin 3'b110 - Use TIMERIO6 pin 3'b111 - Use TIMERIO7 pin
0x6238 CFG0_TIMER14_CTRL_PROXY — Controls TIMER14 operation
  [2:0] TIMER14_CTRL_CAP_SEL_PROXY — Selects the TIMERIO input pin for capture input signal. This control is only used when TIMER14 is configured for capture operation. Field values (Others are reserved): 3'b000 - Use TIMERIO0 pin 3'b001 - Use TIMERIO1 pin 3'b010 - Use TIMERIO2 pin 3'b011 - Use TIMERIO3 pin 3'b100 - Use TIMERIO4 pin 3'b101 - Use TIMERIO5 pin 3'b110 - Use TIMERIO6 pin 3'b111 - Use TIMERIO7 pin
0x623C CFG0_TIMER15_CTRL_PROXY — Controls TIMER15 operation
  [8] TIMER15_CTRL_CASCADE_EN_PROXY — Enables cascading of TIMER15 to TIMER14
  [2:0] TIMER15_CTRL_CAP_SEL_PROXY — Selects the TIMERIO input pin for capture input signal. This control is only used when TIMER15 is configured for capture operation. Field values (Others are reserved): 3'b000 - Use TIMERIO0 pin 3'b001 - Use TIMERIO1 pin 3'b010 - Use TIMERIO2 pin 3'b011 - Use TIMERIO3 pin 3'b100 - Use TIMERIO4 pin 3'b101 - Use TIMERIO5 pin 3'b110 - Use TIMERIO6 pin 3'b111 - Use TIMERIO7 pin
0x6240 CFG0_TIMER16_CTRL_PROXY — Controls TIMER16 operation
  [2:0] TIMER16_CTRL_CAP_SEL_PROXY — Selects the TIMERIO input pin for capture input signal. This control is only used when TIMER16 is configured for capture operation. Field values (Others are reserved): 3'b000 - Use TIMERIO0 pin 3'b001 - Use TIMERIO1 pin 3'b010 - Use TIMERIO2 pin 3'b011 - Use TIMERIO3 pin 3'b100 - Use TIMERIO4 pin 3'b101 - Use TIMERIO5 pin 3'b110 - Use TIMERIO6 pin 3'b111 - Use TIMERIO7 pin
0x6244 CFG0_TIMER17_CTRL_PROXY — Controls TIMER17 operation
  [8] TIMER17_CTRL_CASCADE_EN_PROXY — Enables cascading of TIMER17 to TIMER16
  [2:0] TIMER17_CTRL_CAP_SEL_PROXY — Selects the TIMERIO input pin for capture input signal. This control is only used when TIMER17 is configured for capture operation. Field values (Others are reserved): 3'b000 - Use TIMERIO0 pin 3'b001 - Use TIMERIO1 pin 3'b010 - Use TIMERIO2 pin 3'b011 - Use TIMERIO3 pin 3'b100 - Use TIMERIO4 pin 3'b101 - Use TIMERIO5 pin 3'b110 - Use TIMERIO6 pin 3'b111 - Use TIMERIO7 pin
0x6248 CFG0_TIMER18_CTRL_PROXY — Controls TIMER18 operation
  [2:0] TIMER18_CTRL_CAP_SEL_PROXY — Selects the TIMERIO input pin for capture input signal. This control is only used when TIMER18 is configured for capture operation. Field values (Others are reserved): 3'b000 - Use TIMERIO0 pin 3'b001 - Use TIMERIO1 pin 3'b010 - Use TIMERIO2 pin 3'b011 - Use TIMERIO3 pin 3'b100 - Use TIMERIO4 pin 3'b101 - Use TIMERIO5 pin 3'b110 - Use TIMERIO6 pin 3'b111 - Use TIMERIO7 pin
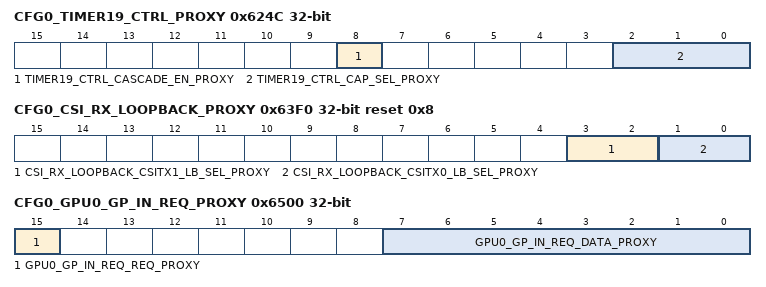
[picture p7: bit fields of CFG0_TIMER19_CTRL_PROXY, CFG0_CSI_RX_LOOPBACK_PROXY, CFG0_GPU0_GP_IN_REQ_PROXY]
0x624C CFG0_TIMER19_CTRL_PROXY — Controls TIMER19 operation
  [8] TIMER19_CTRL_CASCADE_EN_PROXY — Enables cascading of TIMER19 to TIMER18
  [2:0] TIMER19_CTRL_CAP_SEL_PROXY — Selects the TIMERIO input pin for capture input signal. This control is only used when TIMER19 is configured for capture operation. Field values (Others are reserved): 3'b000 - Use TIMERIO0 pin 3'b001 - Use TIMERIO1 pin 3'b010 - Use TIMERIO2 pin 3'b011 - Use TIMERIO3 pin 3'b100 - Use TIMERIO4 pin 3'b101 - Use TIMERIO5 pin 3'b110 - Use TIMERIO6 pin 3'b111 - Use TIMERIO7 pin
{0x6280+4i} CFG0_TIMERIO{i}_CTRL_PROXY (i=0..7) — Controls Timer IO muxing
  [4:0] TIMERIO{i}_CTRL_OUT_SEL_PROXY — Selects the source of the TIMERIO{i} output Field values (Others are reserved): 5'b00000 - TIMERIO{i} is driven by TIMER0 output 5'b00001 - TIMERIO{i} is driven by TIMER1 output 5'b00010 - TIMERIO{i} is driven by TIMER2 output 5'b00011 - TIMERIO{i} is driven by TIMER3 output 5'b00100 - TIMERIO{i} is driven by TIMER4 output 5'b00101 - TIMERIO{i} is driven by TIMER5 output 5'b00110 - TIMERIO{i} is driven by TIMER6 output 5'b00111 - TIMERIO{i} is driven by TIMER7 output 5'b01000 - TIMERIO{i} is driven by TIMER8 output 5'b01001 - TIMERIO{i} is driven by TIMER9 output 5'b01010 - TIMERIO{i} is driven by TIMER10 output 5'b01011 - TIMERIO{i} is driven by TIMER11 output 5'b01100 - TIMERIO{i} is driven by TIMER12 output 5'b01101 - TIMERIO{i} is driven by TIMER13 output 5'b01110 - TIMERIO{i} is driven by TIMER14 output 5'b01111 - TIMERIO{i} is driven by TIMER15 output 5'b10000 - TIMERIO{i} is driven by TIMER16 output 5'b10001 - TIMERIO{i} is driven by TIMER17 output 5'b10010 - TIMERIO{i} is driven by TIMER18 output 5'b10011 - TIMERIO{i} is driven by TIMER19 output
0x62E0 CFG0_I2C0_CTRL_PROXY — Controls I2C0 operation for open drain I/Os
  [0] I2C0_CTRL_HS_MCS_EN_PROXY — HS Mode master current source enable.When set, enables the current-source pull-up on the SCL output. Only one master on the I2C bus should enable SCL current sourcing.
0x6300 CFG0_DPHY_TX0_CTRL_PROXY — Controls DPHY_TX0 operation
  [1:0] DPHY_TX0_CTRL_LANE_FUNC_SEL_PROXY — Selects the source for the 4 lanes of DPHY_TX 0 Field values (Others are reserved): 2'b00 - IP1 (DSI_0 PPI0) 2'b01 - IP2 (CSI-TX0)
0x6304 CFG0_DPHY_TX1_CTRL_PROXY — Controls DPHY_TX1 operation
  [1:0] DPHY_TX1_CTRL_LANE_FUNC_SEL_PROXY — Selects the source for the 4 lanes of DPHY_TX 1 Field values (Others are reserved): 2'b00 - IP1 (DSI_1 PPI0) 2'b01 - IP2 (CSI-TX1)
0x6310 CFG0_EDP0_CTRL_PROXY — Controls eDP0 operation
  [8] EDP0_CTRL_RESET_ISO_PROXY — Reset isolationWhen set, enables reset isolation of eDP PHY
0x6320 CFG0_VPAC0_CAL0_CTRL_PROXY — Controls VPAC0 Camera Adaptive Layer 0 interface operation
  [1:0] VPAC0_CAL0_CTRL_CAL_SEL_PROXY — Selects the CSI_RX source for the VPAC CAL0 input Field values (Others are reserved): 2'b00 - CSI-RX 0 2'b01 - CSI-RX 1 2'b10 - CSI-RX 2 2'b11 - Reserved
0x6330 CFG0_VPAC1_CAL0_CTRL_PROXY — Controls VPAC1 Camera Adaptive Layer 0 interface operation
  [1:0] VPAC1_CAL0_CTRL_CAL_SEL_PROXY — Selects the CSI_RX source for the VPAC CAL0 input Field values (Others are reserved): 2'b00 - CSI-RX 0 2'b01 - CSI-RX 1 2'b10 - CSI-RX 2 2'b11 - Reserved
0x63F0 CFG0_CSI_RX_LOOPBACK_PROXY reset 0x8 — Controls loopback of CSI-RX inputs to CSI-TX inputs for diagnostics.
  [3:2] CSI_RX_LOOPBACK_CSITX1_LB_SEL_PROXY — Selects the CSI-RX loopback source for CSI-TX1 Field values (Others are reserved): 2'b00 - CSI-RX 0 2'b01 - CSI-RX 1 2'b10 - CSI-RX 2 2'b11 - Reserved
  [1:0] CSI_RX_LOOPBACK_CSITX0_LB_SEL_PROXY — Selects the CSI-RX loopback source for CSI-TX0. Field values (Others are reserved): 2'b00 - CSI-RX 0 2'b01 - CSI-RX 1 2'b10 - CSI-RX 2 2'b11 - Reserved
0x6500 CFG0_GPU0_GP_IN_REQ_PROXY — Generates GPIO input event to GPU0
  [15] GPU0_GP_IN_REQ_REQ_PROXY — Input request. This bit is set to generate a GPIO request to the GPU to read the requestor data input. This bit should be cleared by the requestor after the GPU has acknowledged the request.
  [7:0] GPU0_GP_IN_REQ_DATA_PROXY — GPIO requestor data input to the GPU
